# CY8C4xxx register map
File version: 0.1
Registers are 8-bit, read-write, no defined reset value unless marked. A register's access mark holds for its fields unless they carry their own. Offsets are from the block's base; [hi:lo] are bit positions; {n}, {i} and the like mark numbered series; 'fields as' and 'values as' point back to an identical list; <NAME> marks a mode.

## TST — Test Subsystem
Base 0x40030000
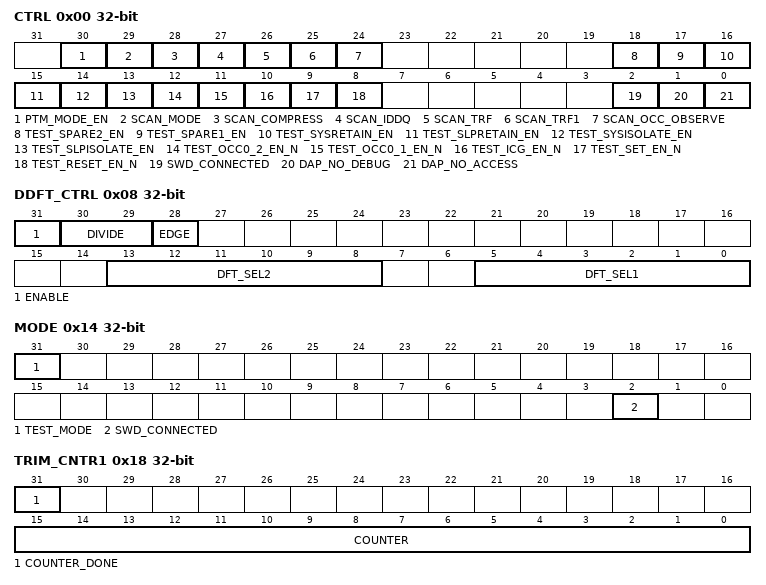
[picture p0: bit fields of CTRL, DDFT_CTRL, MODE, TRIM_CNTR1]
0x00 CTRL 32-bit — Main Test Control Register
  [30] PTM_MODE_EN — 0: PTM interface disabled?1: PTM interface enabled (only when SCAN_MODE=0)
  [29] SCAN_MODE write-once — 0: Normal (non-scan) mode?1: Scan mode enabled?Setting this bit will cause scan mode to activate, after which SWD ports stops operating (it is itself scannable) and no other register accesses can be made. This bit will override PTM_MODE_EN when set.
  [28] SCAN_COMPRESS — 0: Uncompressed scan test?1: Compressed scan test
  [27] SCAN_IDDQ — 0: Normal scan test?1: IDDQ scan test (can be used concurrent with SCAN_COMPRESS but not SCAN_TRF).
  [26] SCAN_TRF — 0: Normal (SAF/IDDQ) scan test?1: Transition Fault scan test (can be used concurrent with SCAN_COMPRESS but not SCAN_IDDQ).
  [25] SCAN_TRF1 — 0: Do not include <48MHz logic in TRF when SCAN_TRF=1?1: Include <48MHz logic in TRF when SCAN_TRF=1
  [24] SCAN_OCC_OBSERVE — 0: Normal scan mode?1: Bring out OCC clock on scan_out[0]
  [18] TEST_SPARE2_EN — Enable bit for spare signal in scan control chain. See SAS for more details.
  [17] TEST_SPARE1_EN — Enable bit for spare signal in scan control chain. See SAS for more details.
  [16] TEST_SYSRETAIN_EN — Enable sleepb test points for retention registers in Active domain. This bit is further gated using a scan control chain. See SAS for more details.
  [15] TEST_SLPRETAIN_EN — Enable sleepb test points for retention registers in DeepSleep domain. This bit is further gated using a scan control chain. See SAS for more details.
  [14] TEST_SYSISOLATE_EN — Enable sleep test points in Active domain. This bit is further gated using a scan control chain. See SAS for more details.
  [13] TEST_SLPISOLATE_EN — Enable sleep test points in DeepSleep domain. This bit is further gated using a scan control chain. See SAS for more details.
  [12] TEST_OCC0_2_EN_N — Enable the OCC test point of Bit 2 in TRF mode. This bit is further gated using a scan control chain. See SAS for more details.
  [11] TEST_OCC0_1_EN_N — Enable the OCC test point of Bit 1 in TRF mode. This bit is further gated using a scan control chain. See SAS for more details.
  [10] TEST_ICG_EN_N — Enable clock gater test points during scan. This bit is further gated using a scan control chain. See SAS for more details.
  [9] TEST_SET_EN_N — Enable async set test points during scan. This bit is further gated using a scan control chain. See SAS for more details.
  [8] TEST_RESET_EN_N — Enable async reset test points during scan. This bit is further gated using a scan control chain. See SAS for more details.
  [2] SWD_CONNECTED ro — 0: SWD not active?1: SWD activated (Line Reset & Connect sequence passed)?(Note this bit is duplicated in TST_MODE.SWD_CONNECTED for user mode access)
  [1] DAP_NO_DEBUG write-once — 1: Block all AHB accesses to CM0 Debug (PPB) Registers (effectively disabling debugger capability).
  [0] DAP_NO_ACCESS write-once — 1: Block all AHB accesses from SWD port (effectively disabling it)
0x04 ADFT_CTRL 32-bit — Analog DFT Control Register
  [31] ENABLE — Enables ADFT functionality. Must be set for any of the ADFT switches and muxes to operate.
0x08 DDFT_CTRL 32-bit — Digital DFT Control Register
  [31] ENABLE — 1: Enables DDFT functionality. Connects output of DDFT mux to designated DDFT pin.
  [30:29] DIVIDE — Controls in-line divider for DDFT output #1 (used for high-speed clock measurements).
    0=DIRECT; 1=DIV_BY_2; 2=DIV_BY_4; 3=DIV_BY_8
  [28] EDGE — Edge sensitivity for in-line divider on DDFT output #1 (only relevant when DIVIDE>0).
    0=POSEDGE; 1=NEGEDGE
  [13:8] DFT_SEL2 — Select signal for DDFT output #2
    0=VSS; 1=CLK1; 2=CLK2; 3=PWR1; 4=PWR2; 5=VMON; 6=TSS_VDDA_OK; 7=ADFT_TRIP1; 8=ADFT_TRIP2; {v}=TSS{v-8} (v=9..12); 13=I2CS_CLK_I2CS; 14=I2CS_SDAIN_SI
  [5:0] DFT_SEL1 — Select signal for DDFT output #1
    values as DFT_SEL2
0x14 MODE 32-bit — Test Mode Control Register
  [31] TEST_MODE — 0: Normal operation mode?1: Test mode (any test mode)?Setting this bit will prevent BootROM from yielding execution to Flash image.
  [2] SWD_CONNECTED ro — 0: SWD not active?1: SWD activated (Line Reset & Connect sequence passed)?(Note: this bit is a duplicate of TST_CTRL.SWD_CONNECTED and is present in all M0S8 products except TSG4)
0x18 TRIM_CNTR1 32-bit — IMO trim down-counter and status (clk_sys)
  [31] COUNTER_DONE ro — Status bit indicating that TRIM_CNTR1.COUNTER==0 and TRIM_CNT2.COUNTER stopped counting up
  [15:0] COUNTER — Down-counter clocked on clk_sys. By writing non-zero value to this counter TRIM_CNTR2.COUNTER clears and counts up. TRIM_CNTR1.COUNTER counts down until TRIM_CNTR1.COUNTER==0
0x1C TRIM_CNTR2 32-bit — IMO trim up-counter (ddft)
  [15:0] COUNTER ro — Up-counter clocked on DDFT output #2. When TRIM_CNTR1.COUNT_DONE==1 counter stopped and can be read by SW
